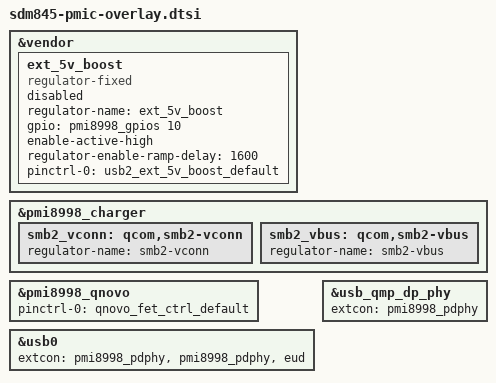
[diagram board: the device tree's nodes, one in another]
// SPDX-License-Identifier: GPL-2.0-only
/*
 * Copyright (c) 2017-2018, The Linux Foundation. All rights reserved.
 */

#include <dt-bindings/gpio/gpio.h>

#include "pmi8998.dtsi"

&vendor {
	ext_5v_boost: ext_5v_boost {
		status = "disabled";
		compatible = "regulator-fixed";
		regulator-name = "ext_5v_boost";
		gpio = <&pmi8998_gpios 10 GPIO_ACTIVE_HIGH>;
		enable-active-high;

		regulator-enable-ramp-delay = <1600>;
		pinctrl-names = "default";
		pinctrl-0 = <&usb2_ext_5v_boost_default>;
	};
};

&pmi8998_charger {
	smb2_vconn: qcom,smb2-vconn {
		regulator-name = "smb2-vconn";
	};
	smb2_vbus: qcom,smb2-vbus {
		regulator-name = "smb2-vbus";
	};
};

&pmi8998_qnovo {
	pinctrl-names = "default";
	pinctrl-0 = <&qnovo_fet_ctrl_default>;
};

&usb0 {
	extcon = <&pmi8998_pdphy>, <&pmi8998_pdphy>, <&eud>;
};

&usb_qmp_dp_phy {
	extcon = <&pmi8998_pdphy>;
};
